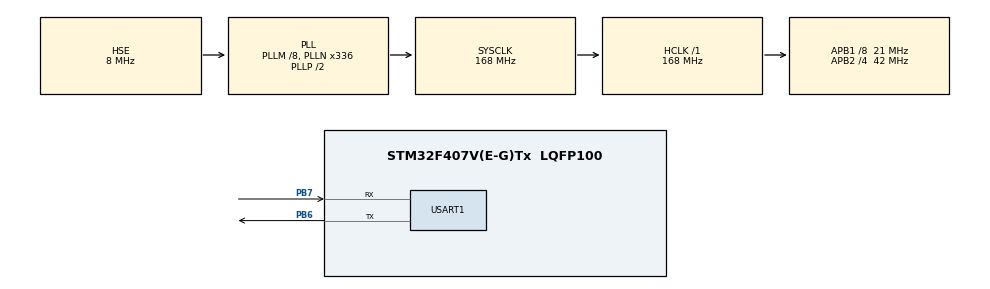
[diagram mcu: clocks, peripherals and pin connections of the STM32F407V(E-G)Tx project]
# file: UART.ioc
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Mcu.Family=STM32F4
Mcu.Name=STM32F407V(E-G)Tx
Mcu.Package=LQFP100
NVIC.PriorityGroup=NVIC_PRIORITYGROUP_0
PB6.Mode=Asynchronous
PB6.Signal=USART1_TX
PB7.Mode=Asynchronous
PB7.Signal=USART1_RX
PH0-OSC_IN.Mode=HSE-External-Oscillator
PH0-OSC_IN.Signal=RCC_OSC_IN
PH1-OSC_OUT.Mode=HSE-External-Oscillator
PH1-OSC_OUT.Signal=RCC_OSC_OUT
ProjectManager.HeapSize=0x200
ProjectManager.StackSize=0x400
ProjectManager.TargetToolchain=MDK-ARM V5.27
RCC.48MHZClocksFreq_Value=48000000
RCC.AHBFreq_Value=168000000
RCC.APB1CLKDivider=RCC_HCLK_DIV8
RCC.APB1Freq_Value=21000000
RCC.APB1TimFreq_Value=42000000
RCC.APB2CLKDivider=RCC_HCLK_DIV4
RCC.APB2Freq_Value=42000000
RCC.APB2TimFreq_Value=84000000
RCC.CortexFreq_Value=168000000
RCC.HCLKFreq_Value=168000000
RCC.HSE_VALUE=8000000
RCC.HSI_VALUE=16000000
RCC.LSE_VALUE=32768
RCC.PLLM=8
RCC.PLLN=336
RCC.PLLQ=7
RCC.PLLSourceVirtual=RCC_PLLSOURCE_HSE
RCC.SYSCLKFreq_VALUE=168000000
RCC.SYSCLKSource=RCC_SYSCLKSOURCE_PLLCLK
RCC.VCOOutputFreq_Value=336000000
USART1.VirtualMode=VM_ASYNC
board=STM32F407G-DISC1

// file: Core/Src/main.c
/* USER CODE BEGIN Header */
/**
  ******************************************************************************
  * @file           : main.c
  * @brief          : Main program body
  ******************************************************************************
  * @attention
  *
  * <h2><center>&copy; Copyright (c) 2020 STMicroelectronics.
  * All rights reserved.</center></h2>
  *
  * This software component is licensed by ST under BSD 3-Clause license,
  * the "License"; You may not use this file except in compliance with the
  * License. You may obtain a copy of the License at:
  *                        opensource.org/licenses/BSD-3-Clause
  *
  ******************************************************************************
  */
/* USER CODE END Header */

#include "main.h"

/* USER CODE BEGIN Includes */
#include "H:\Jorge\UPM\master\TFM\PruebaARM\UART_COBS\MDK-ARM\cobs2.h"
#include <stdio.h>
#include <stdlib.h>
#include <string.h>
#include <stdio.h>

//#include <time.h>

/* USER CODE END Includes */

UART_HandleTypeDef huart1;

uint8_t c = 0x32;
uint8_t ifup[] = {0x00, 0x00, 0x10, 0x08, 0x18};
uint8_t ifdown[] = {0x00, 0x00, 0x10, 0x07, 0x17};
uint8_t ComClear[] = {0x00, 0x00, 0x10, 0x00, 0x10};
uint8_t Reset[] = {0x00, 0x00, 0x10, 0x03, 0x13};
uint8_t Status[] = {0x00, 0x00, 0x11, 0x05, 0x14}; //Look the answer in the KBI pdf
uint8_t ReadChannel[] = {0x00, 0x00, 0x11, 0x12, 0x03};
uint8_t WriteChannel[] = {0x00, 0x01, 0x10, 0x12, 0x0c, 0x0F}; //Channel 15 predefined, change last uint8_t to change channell between 11-26
uint8_t ReadRole[] = {0x00, 0x00, 0x11, 0x19, 0x08};
uint8_t WriteRole[] = {0x00, 1, 16, 25, 11, 3}; //FED, look the table below and change the last uint8_t

/* //CKS for WriteRole
  0 = Not Configured
  1 = Router -- CKS = 09
  2 = REED (Router Elegible End Device) -- CKS = 0A
  3 = FED (Full End Device) -- CKS = OB
  4 = MED (Minimal End Device) -- CKS = 0C
  5 = SED (Sleepy End Device) CKS = 0D
  6 = Leader -- CKS = 0E

  Modifications conditions
  Status must be none, except none - saved configuration. Also allowed when status is joined to trigger some
  role transition mechanisms (SED ? MED, SED ? FED, MED? FED).
*/

uint8_t ReadJoinCred[] = {0x00, 0x00, 0x11, 0x17, 0x06};
uint8_t WriteJoinCred[] = {0x00, 0x10, 0x10, 0x17, 0x69, 0x38, 0x34, 0x30, 0x34, 0x44, 0x32, 0x30, 0x30, 0x30, 0x30, 0x30, 0x30, 0x30, 0x35, 0x46, 0x43};

	/* Network out of band parameters */
#define NET_ROLE CMDS_ROLE_FED

#define NET_CHANNEL CMDS_CHANNEL_15
#define NET_PANID "1234"
#define NET_NAME "KBI Network"
#define NET_PREFIX "FD00:0DB8:0000:0000::"
#define NET_KEY "00112233445566778899aabbccddeeff"
#define NET_EXT_PANID "000db80000000000"
#define NET_COMM_CRED "KIRALE"

/* Application parameters */
#define SERVER_UDP_PORT 7485
#define CLIENT_UDP_PAYLOAD "Hello, world!"
#define TEST_DURATION 30

void SystemClock_Config(void);
static void MX_GPIO_Init(void);
static void MX_USART1_UART_Init(void);

static void send(uint8_t *buffer, size_t size);
static void receive(uint8_t *buffer, size_t size);
static void InicioFed(void);
static void uptate(void);

static void hextobin( const char *str, uint8_t *dst, size_t len );

int main(void)
{

  /* MCU Configuration--------------------------------------------------------*/

  /* Reset of all peripherals, Initializes the Flash interface and the Systick. */
  HAL_Init();

  /* Configure the system clock */
  SystemClock_Config();

  /* Initialize all configured peripherals */
  MX_GPIO_Init();
	MX_USART1_UART_Init();

	InicioFed();

  while (1)
  {
    /* USER CODE END WHILE */

	//Channel

		HAL_Delay(200);
  }
}

void SystemClock_Config(void)
{
  RCC_OscInitTypeDef RCC_OscInitStruct = {0};
  RCC_ClkInitTypeDef RCC_ClkInitStruct = {0};

  /** Configure the main internal regulator output voltage
  */
  __HAL_RCC_PWR_CLK_ENABLE();
  __HAL_PWR_VOLTAGESCALING_CONFIG(PWR_REGULATOR_VOLTAGE_SCALE1);
  /** Initializes the RCC Oscillators according to the specified parameters
  * in the RCC_OscInitTypeDef structure.
  */
  RCC_OscInitStruct.OscillatorType = RCC_OSCILLATORTYPE_HSE;
  RCC_OscInitStruct.HSEState = RCC_HSE_ON;
  RCC_OscInitStruct.PLL.PLLState = RCC_PLL_ON;
  RCC_OscInitStruct.PLL.PLLSource = RCC_PLLSOURCE_HSE;
  RCC_OscInitStruct.PLL.PLLM = 8;
  RCC_OscInitStruct.PLL.PLLN = 336;
  RCC_OscInitStruct.PLL.PLLP = RCC_PLLP_DIV2;
  RCC_OscInitStruct.PLL.PLLQ = 7;
  if (HAL_RCC_OscConfig(&RCC_OscInitStruct) != HAL_OK)
  {
    Error_Handler();
  }
  /** Initializes the CPU, AHB and APB buses clocks
  */
  RCC_ClkInitStruct.ClockType = RCC_CLOCKTYPE_HCLK|RCC_CLOCKTYPE_SYSCLK
                              |RCC_CLOCKTYPE_PCLK1|RCC_CLOCKTYPE_PCLK2;
  RCC_ClkInitStruct.SYSCLKSource = RCC_SYSCLKSOURCE_PLLCLK;
  RCC_ClkInitStruct.AHBCLKDivider = RCC_SYSCLK_DIV1;
  RCC_ClkInitStruct.APB1CLKDivider = RCC_HCLK_DIV8;
  RCC_ClkInitStruct.APB2CLKDivider = RCC_HCLK_DIV4;

  if (HAL_RCC_ClockConfig(&RCC_ClkInitStruct, FLASH_LATENCY_5) != HAL_OK)
  {
    Error_Handler();
  }
}

static void hextobin( const char *str, uint8_t *dst, size_t len )
{
  uint8_t pos, i0, i1;

  /* Mapping of ASCII characters to hex values */
  const uint8_t hashmap[] = {
      0x00, 0x01, 0x02, 0x03, 0x04, 0x05, 0x06, 0x07, // 01234567
      0x08, 0x09, 0x00, 0x00, 0x00, 0x00, 0x00, 0x00, // 89:;<=>?
      0x00, 0x0a, 0x0b, 0x0c, 0x0d, 0x0e, 0x0f, 0x00, // @ABCDEFG
      0x00, 0x00, 0x00, 0x00, 0x00, 0x00, 0x00, 0x00, // HIJKLMNO
  };

  for ( pos = 0; ( ( pos < ( len * 2 ) ) && ( pos < strlen( str ) ) );
        pos += 2 )
  {
    i0             = ( ( uint8_t ) str[ pos + 0 ] & 0x1F ) ^ 0x10;
    i1             = ( ( uint8_t ) str[ pos + 1 ] & 0x1F ) ^ 0x10;
    dst[ pos / 2 ] = ( uint8_t )( hashmap[ i0 ] << 4 ) | hashmap[ i1 ];
  };
}

static void MX_USART1_UART_Init(void)
{
  huart1.Instance = USART1;
  huart1.Init.BaudRate = 115200;
  huart1.Init.WordLength = UART_WORDLENGTH_8B;
  huart1.Init.StopBits = UART_STOPBITS_1;
  huart1.Init.Parity = UART_PARITY_NONE;
  huart1.Init.Mode = UART_MODE_TX_RX;
  huart1.Init.HwFlowCtl = UART_HWCONTROL_NONE;
  huart1.Init.OverSampling = UART_OVERSAMPLING_16;
  if (HAL_UART_Init(&huart1) != HAL_OK)
  {
    Error_Handler();
  }
}

static void MX_GPIO_Init(void)
{

  /* GPIO Ports Clock Enable */
  __HAL_RCC_GPIOH_CLK_ENABLE();
  __HAL_RCC_GPIOB_CLK_ENABLE();

}

/* USER CODE BEGIN 4 */
static  void InicioFed(void)
{
	uint8_t *encodedbuffer;
	uint8_t *receivebuffer;
	uint8_t *decodedbuffer;
	size_t encodedsize;

	//Channel
	HAL_Delay(1000);

	send(WriteChannel,(sizeof(WriteChannel)/sizeof(WriteChannel[0])));
	HAL_UART_Receive(&huart1, receivebuffer,512,1000);
	decode(receivebuffer,sizeof(receivebuffer), decodedbuffer);

	//Role
	HAL_Delay(100);
	send(WriteRole,(sizeof(WriteRole)/sizeof(WriteRole[0])));
	HAL_UART_Receive(&huart1, receivebuffer,512,1000);
	decode(receivebuffer,sizeof(receivebuffer),decodedbuffer);

	//Join Credential

	send(WriteChannel,(sizeof(WriteJoinCred)/sizeof(WriteJoinCred[0])));
	HAL_UART_Receive(&huart1, receivebuffer,512,1000);
	decode(receivebuffer,sizeof(receivebuffer),decodedbuffer);

	//IFUP
	send(ifup,(sizeof(ifup)/sizeof(ifup[0])));
	HAL_UART_Receive(&huart1, receivebuffer,512,1000);
	decode(receivebuffer,sizeof(receivebuffer),decodedbuffer);
}

static void send(uint8_t *buffer, size_t size)
{
	uint8_t PacketMarker = 0;
	uint8_t _encodeBuffer[getEncodedBufferSize(size)];
	size_t numEncoded = encode(buffer, size, _encodeBuffer);
	HAL_UART_Transmit(&huart1,_encodeBuffer,numEncoded,1000);
	HAL_UART_Transmit(&huart1,&PacketMarker,sizeof(PacketMarker),1000);
}

static void receive(uint8_t *buffer, size_t size)
{

	uint8_t PacketMarker = 0;

	uint8_t *receivebuffer;
	uint8_t *decodedbuffer;

	HAL_UART_Receive(&huart1, receivebuffer,512,1000);
	decode(receivebuffer,sizeof(receivebuffer),decodedbuffer);

}

void Error_Handler(void)
{
}

/************************ (C) COPYRIGHT STMicroelectronics *****END OF FILE****/
